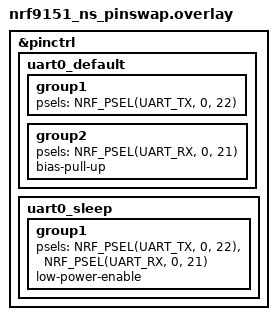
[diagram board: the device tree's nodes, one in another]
/*
 * MTIB REV 1.1 UART pin swap compensation — nRF9151 (Alpha B0).
 *
 * REV 1.1 carrier board has UART TX/RX traces physically swapped.
 * This overlay swaps the nRF9151 UART0 pin assignments to compensate.
 * Not needed on REV 1.2 (fixed in hardware).
 *
 * Base DTS: TX=P0.21, RX=P0.22
 * This overlay: TX=P0.22, RX=P0.21 (swapped)
 *
 * Apply via: -DDTC_OVERLAY_FILE="...;overlays/nrf9151_ns_pinswap.overlay"
 */

&pinctrl {
    uart0_default: uart0_default {
        group1 {
            psels = <NRF_PSEL(UART_TX, 0, 22)>;
        };
        group2 {
            psels = <NRF_PSEL(UART_RX, 0, 21)>;
            bias-pull-up;
        };
    };

    uart0_sleep: uart0_sleep {
        group1 {
            psels = <NRF_PSEL(UART_TX, 0, 22)>,
                    <NRF_PSEL(UART_RX, 0, 21)>;
            low-power-enable;
        };
    };
};
